# STM32H730 register map
File version: 1.2
CPU: CM7 r0p1, little endian, MPU, FPU, 4 interrupt priority bits
Registers are 32-bit, read-write, reset 0x0 unless marked. A register's access mark holds for its fields unless they carry their own. Offsets are from the block's base; [hi:lo] are bit positions; lines under a group give offsets from that group; {n}, {i} and the like mark numbered series; 'fields as' and 'values as' point back to an identical list.

## MDIOS — Management data input/output slave
Base 0x40009400
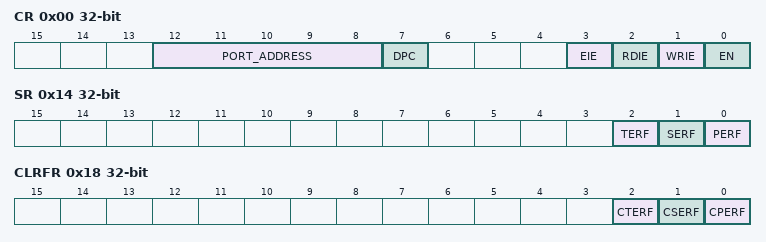
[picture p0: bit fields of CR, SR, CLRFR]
0x00 CR — MDIOS configuration register
  [12:8] PORT_ADDRESS — Slaves's address
  [7] DPC — Disable Preamble Check
  [3] EIE — Error interrupt enable
  [2] RDIE — Register Read Interrupt Enable
  [1] WRIE — Register write interrupt enable
  [0] EN — Peripheral enable
0x04 WRFR ro — MDIOS write flag register
  [31:0] WRF — Write flags for MDIO registers 0 to 31
0x08 CWRFR — MDIOS clear write flag register
  [31:0] CWRF — Clear the write flag
0x0C RDFR ro — MDIOS read flag register
  [31:0] RDF — Read flags for MDIO registers 0 to 31
0x10 CRDFR — MDIOS clear read flag register
  [31:0] CRDF — Clear the read flag
0x14 SR ro — MDIOS status register
  [2] TERF — Turnaround error flag
  [1] SERF — Start error flag
  [0] PERF — Preamble error flag
0x18 CLRFR — MDIOS clear flag register
  [2] CTERF — Clear the turnaround error flag
  [1] CSERF — Clear the start error flag
  [0] CPERF — Clear the preamble error flag
{0x1C+4i} DINR{i} ro (i=0..31) — MDIOS input data register {i}
  [15:0] DIN{i} — Input data received from MDIO Master during write frames
{0x9C+4i} DOUTR{i} (i=0..31) — MDIOS output data register {i}
  [15:0] DOUT{i} — Output data sent to MDIO Master during read frames

## OPAMP — Operational amplifiers
Base 0x40009000
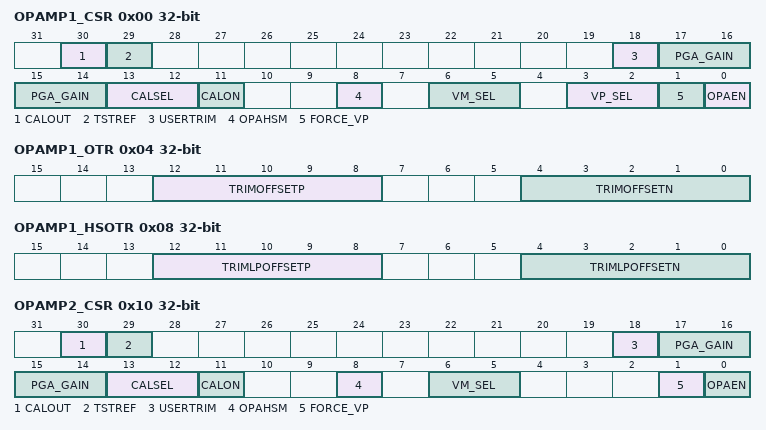
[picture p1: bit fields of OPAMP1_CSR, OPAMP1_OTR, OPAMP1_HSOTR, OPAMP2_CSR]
0x00 OPAMP1_CSR — OPAMP1 control/status register
  [30] CALOUT — Operational amplifier calibration output
  [29] TSTREF — OPAMP calibration reference voltage output control (reserved for test)
  [18] USERTRIM — User trimming enable
  [17:14] PGA_GAIN — allows to switch from AOP offset trimmed values to AOP offset
  [13:12] CALSEL — Calibration selection
  [11] CALON — Calibration mode enabled
  [8] OPAHSM — Operational amplifier high-speed mode
  [6:5] VM_SEL — Inverting input selection
  [3:2] VP_SEL — Operational amplifier PGA mode
  [1] FORCE_VP — Force internal reference on VP (reserved for test
  [0] OPAEN — Operational amplifier Enable
0x04 OPAMP1_OTR — OPAMP1 offset trimming register in normal mode
  [12:8] TRIMOFFSETP — Trim for PMOS differential pairs
  [4:0] TRIMOFFSETN — Trim for NMOS differential pairs
0x08 OPAMP1_HSOTR — OPAMP1 offset trimming register in low-power mode
  [12:8] TRIMLPOFFSETP — Trim for PMOS differential pairs
  [4:0] TRIMLPOFFSETN — Trim for NMOS differential pairs
0x10 OPAMP2_CSR — OPAMP2 control/status register
  [30] CALOUT — Operational amplifier calibration output
  [29] TSTREF — OPAMP calibration reference voltage output control (reserved for test)
  [18] USERTRIM — User trimming enable
  [17:14] PGA_GAIN — Operational amplifier Programmable amplifier gain value
  [13:12] CALSEL — Calibration selection
  [11] CALON — Calibration mode enabled
  [8] OPAHSM — Operational amplifier high-speed mode
  [6:5] VM_SEL — Inverting input selection
  [1] FORCE_VP — Force internal reference on VP (reserved for test)
  [0] OPAEN — Operational amplifier Enable
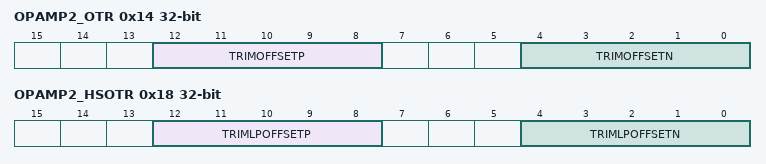
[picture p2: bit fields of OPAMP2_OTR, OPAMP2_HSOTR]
0x14 OPAMP2_OTR — OPAMP2 offset trimming register in normal mode
  fields as OPAMP1_OTR
0x18 OPAMP2_HSOTR — OPAMP2 offset trimming register in low-power mode
  fields as OPAMP1_HSOTR

## OTG1_HS_HOST — USB 1 on the go high speed
Base 0x40040400
Same registers: OTG2_HS_HOST 0x40080400
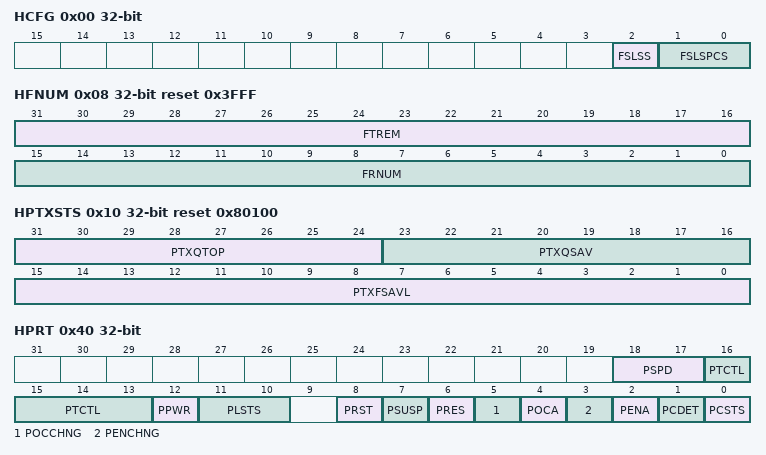
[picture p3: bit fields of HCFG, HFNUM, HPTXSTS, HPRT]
0x00 HCFG access per field — OTG_HS host configuration register
  [2] FSLSS ro — FS- and LS-only support
  [1:0] FSLSPCS rw — FS/LS PHY clock select
0x04 HFIR reset 0xEA60 — OTG_HS Host frame interval register
  [15:0] FRIVL — Frame interval
0x08 HFNUM ro reset 0x3FFF — OTG_HS host frame number/frame time remaining register
  [31:16] FTREM — Frame time remaining
  [15:0] FRNUM — Frame number
0x10 HPTXSTS access per field reset 0x80100 — OTG_HS_Host periodic transmit FIFO/queue status register
  [31:24] PTXQTOP ro — Top of the periodic transmit request queue
  [23:16] PTXQSAV ro — Periodic transmit request queue space available
  [15:0] PTXFSAVL rw — Periodic transmit data FIFO space available
0x14 HAINT ro — OTG_HS Host all channels interrupt register
  [15:0] HAINT — Channel interrupts
0x18 HAINTMSK — OTG_HS host all channels interrupt mask register
  [15:0] HAINTM — Channel interrupt mask
0x40 HPRT access per field — OTG_HS host port control and status register
  [18:17] PSPD ro — Port speed
  [16:13] PTCTL rw — Port test control
  [12] PPWR rw — Port power
  [11:10] PLSTS ro — Port line status
  [8] PRST rw — Port reset
  [7] PSUSP rw — Port suspend
  [6] PRES rw — Port resume
  [5] POCCHNG rw — Port overcurrent change
  [4] POCA ro — Port overcurrent active
  [3] PENCHNG rw — Port enable/disable change
  [2] PENA rw — Port enable
  [1] PCDET rw — Port connect detected
  [0] PCSTS ro — Port connect status
{0x100+0x20*i} HC{i} (i=0..15) group — Host channel
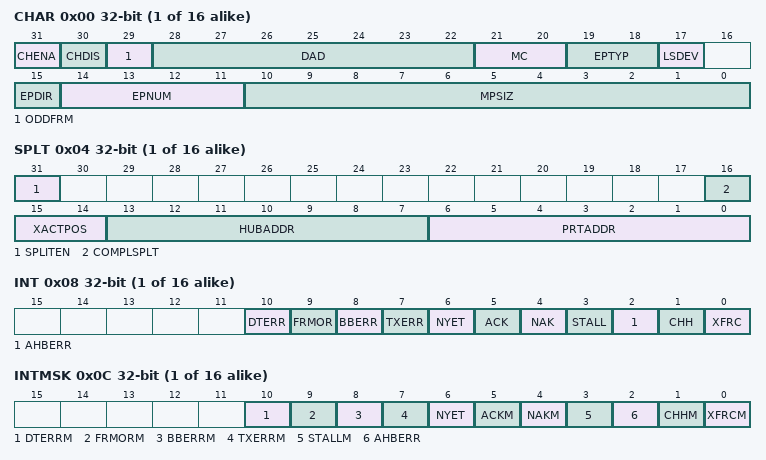
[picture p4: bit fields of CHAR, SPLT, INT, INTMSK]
  0x00 CHAR — OTG_HS host channel-0 characteristics register
    [31] CHENA — Channel enable
    [30] CHDIS — Channel disable
    [29] ODDFRM — Odd frame
    [28:22] DAD — Device address
    [21:20] MC — Multi Count (MC) / Error Count (EC)
    [19:18] EPTYP — Endpoint type
    [17] LSDEV — Low-speed device
    [15] EPDIR — Endpoint direction
    [14:11] EPNUM — Endpoint number
    [10:0] MPSIZ — Maximum packet size
  0x04 SPLT — OTG_HS host channel-0 split control register
    [31] SPLITEN — Split enable
    [16] COMPLSPLT — Do complete split
    [15:14] XACTPOS
    [13:7] HUBADDR — Hub address
    [6:0] PRTADDR — Port address
  0x08 INT — OTG_HS host channel-11 interrupt register
    [10] DTERR — Data toggle error
    [9] FRMOR — Frame overrun
    [8] BBERR — Babble error
    [7] TXERR — Transaction error
    [6] NYET — Response received interrupt
    [5] ACK — ACK response received/transmitted interrupt
    [4] NAK — NAK response received interrupt
    [3] STALL — STALL response received interrupt
    [2] AHBERR — AHB error
    [1] CHH — Channel halted
    [0] XFRC — Transfer completed
  0x0C INTMSK — OTG_HS host channel-11 interrupt mask register
    [10] DTERRM — Data toggle error mask
    [9] FRMORM — Frame overrun mask
    [8] BBERRM — Babble error mask
    [7] TXERRM — Transaction error mask
    [6] NYET — response received interrupt mask
    [5] ACKM — ACK response received/transmitted interrupt mask
    [4] NAKM — NAK response received interrupt mask
    [3] STALLM — STALL response received interrupt mask
    [2] AHBERR — AHB error
    [1] CHHM — Channel halted mask
    [0] XFRCM — Transfer completed mask
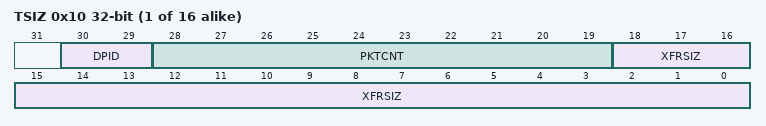
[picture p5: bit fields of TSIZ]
  0x10 TSIZ — OTG_HS host channel-11 transfer size register
    [30:29] DPID — Data PID
    [28:19] PKTCNT — Packet count
    [18:0] XFRSIZ — Transfer size
  0x14 DMA — OTG_HS host channel-0 DMA address register
    [31:0] DMAADDR — DMA address
